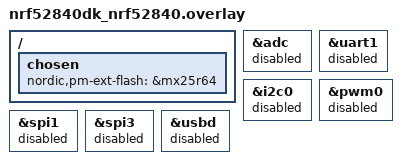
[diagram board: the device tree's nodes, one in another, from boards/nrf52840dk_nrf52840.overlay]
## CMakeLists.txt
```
#
# Copyright (c) 2025 Nordic Semiconductor ASA
#
# SPDX-License-Identifier: LicenseRef-Nordic-5-Clause
#

cmake_minimum_required(VERSION 3.20.0)

find_package(Zephyr HINTS $ENV{ZEPHYR_BASE})

project(matter-contact-sensor)

# Enable GNU STD support.
include(${ZEPHYR_CONNECTEDHOMEIP_MODULE_DIR}/config/nrfconnect/app/enable-gnu-std.cmake)

# NORDIC SDK APP START

# Include all source files that are located in the Matter common directory.
include(${ZEPHYR_NRF_MODULE_DIR}/samples/matter/common/cmake/source_common.cmake)

# Include Data Model utils
include(${ZEPHYR_NRF_MODULE_DIR}/samples/matter/common/cmake/data_model.cmake)

include(${ZEPHYR_NRF_MODULE_DIR}/samples/matter/common/cmake/zap_helpers.cmake)
ncs_get_zap_parent_dir(ZAP_PARENT_DIR)

target_include_directories(app PRIVATE
  src
  ${ZAP_PARENT_DIR}
)

target_sources(app PRIVATE
  src/app_task.cpp
  src/main.cpp
)

ncs_configure_data_model()
# NORDIC SDK APP END
```

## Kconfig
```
#
# Copyright (c) 2025 Nordic Semiconductor
#
# SPDX-License-Identifier: LicenseRef-Nordic-5-Clause
#
mainmenu "Matter nRF Connect Contact Sensor Example Application"

choice OPENTHREAD_NORDIC_LIBRARY_CONFIGURATION
	default OPENTHREAD_NORDIC_LIBRARY_MTD
endchoice

choice OPENTHREAD_DEVICE_TYPE
	default OPENTHREAD_MTD
endchoice

config CHIP_ENABLE_ICD_SUPPORT
	default y

config CHIP_ICD_LIT_SUPPORT
	default y

config CHIP_ICD_SIT_SLOW_POLL_LIMIT
	default 5000

config CHIP_ICD_REPORT_ON_ACTIVE_MODE
	default y

# Reduce Thread TX output power to 0 dBm for SED device
config OPENTHREAD_DEFAULT_TX_POWER
	default 0

source "$(ZEPHYR_CONNECTEDHOMEIP_MODULE_DIR)/config/nrfconnect/chip-module/Kconfig.features"
source "$(ZEPHYR_CONNECTEDHOMEIP_MODULE_DIR)/config/nrfconnect/chip-module/Kconfig.defaults"
source "$(ZEPHYR_NRF_MODULE_DIR)/samples/matter/common/src/Kconfig"
source "Kconfig.zephyr"
```

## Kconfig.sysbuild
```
#
# Copyright (c) 2025 Nordic Semiconductor ASA
#
# SPDX-License-Identifier: LicenseRef-Nordic-5-Clause
#

#### Radio core selection
config NRF_DEFAULT_IPC_RADIO
	default y

# Enable IEEE802.15.4 serialization to network core
# This config automatically pulls in the `overlay-802154.conf` in the ipc_radio image
config NETCORE_IPC_RADIO_IEEE802154
	default y if SOC_SERIES_NRF53

# Enable Bluetooth serialization to network core
# This config automatically pulls in the `bt_hci_ipc.conf` in the ipc_radio image
config NETCORE_IPC_RADIO_BT_HCI_IPC
	default y if SOC_SERIES_NRF53

#### Bootloader
choice BOOTLOADER
	default BOOTLOADER_MCUBOOT
endchoice

if BOOTLOADER_MCUBOOT

#### DFU multi-image support
config DFU_MULTI_IMAGE_PACKAGE_BUILD
	default y

config DFU_MULTI_IMAGE_PACKAGE_APP
	default y

config PM_EXTERNAL_FLASH_MCUBOOT_SECONDARY
	default y

#### DFU network core configuration
if SOC_SERIES_NRF53

config MCUBOOT_UPDATEABLE_IMAGES
	default 2

choice MCUBOOT_MODE
	default MCUBOOT_MODE_OVERWRITE_ONLY
endchoice

choice BOOT_SIGNATURE_TYPE
	default BOOT_SIGNATURE_TYPE_RSA
endchoice

config SECURE_BOOT_NETCORE
	default y

config NETCORE_APP_UPDATE
	default y

config DFU_MULTI_IMAGE_PACKAGE_NET
	default y

endif # SOC_SERIES_NRF53

if BOARD_NRF54L15DK || BOARD_NRF54LM20DK

# Disable checking the external drivers for nRF54L15 and nRF54LM20 DKs.
config PM_OVERRIDE_EXTERNAL_DRIVER_CHECK
	default y

endif # BOARD_NRF54L15DK || BOARD_NRF54LM20DK

endif # BOOTLOADER_MCUBOOT

#### Enable generating factory data
config MATTER_FACTORY_DATA_GENERATE
	default y

source "share/sysbuild/Kconfig"
```

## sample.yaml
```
sample:
  description: Matter Contact Sensor example
  name: Matter Contact Sensor
common:
  tags:
    - sysbuild
    - ci_samples_matter
tests:
  sample.matter.contact_sensor.debug:
    sysbuild: true
    build_only: true
    integration_platforms:
      - nrf54lm20dk/nrf54lm20b/cpuapp
      - nrf54lm20dk/nrf54lm20a/cpuapp
    platform_allow:
      - nrf52840dk/nrf52840
      - nrf5340dk/nrf5340/cpuapp
      - nrf54l15dk/nrf54l15/cpuapp
      - nrf54lm20dk/nrf54lm20b/cpuapp
      - nrf54lm20dk/nrf54lm20a/cpuapp
  sample.matter.contact_sensor.release:
    sysbuild: true
    build_only: true
    extra_args:
      - FILE_SUFFIX=release
    integration_platforms:
      - nrf54lm20dk/nrf54lm20b/cpuapp
      - nrf54lm20dk/nrf54lm20a/cpuapp
    platform_allow:
      - nrf52840dk/nrf52840
      - nrf5340dk/nrf5340/cpuapp
      - nrf54l15dk/nrf54l15/cpuapp
      - nrf54lm20dk/nrf54lm20b/cpuapp
      - nrf54lm20dk/nrf54lm20a/cpuapp
```

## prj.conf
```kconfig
#
# Copyright (c) 2025 Nordic Semiconductor ASA
#
# SPDX-License-Identifier: LicenseRef-Nordic-5-Clause
#

# Enable CHIP
CONFIG_CHIP=y
CONFIG_CHIP_PROJECT_CONFIG="src/chip_project_config.h"
CONFIG_CHIP_DEVICE_PRODUCT_NAME="Matter Contact Sensor"

# Configure ZAP file name
CONFIG_NCS_SAMPLE_MATTER_ZAP_FILE_PATH="${APPLICATION_CONFIG_DIR}/src/default_zap/contact_sensor.zap"

# 32768 == 0x8000 (example Product ID added temporaly,
# as there is no assigned PID on the following list:
# https://github.com/project-chip/connectedhomeip/blob/482e6fd03196a6de45465a90003947ef4b86e0b1/docs/examples/discussion/PID_allocation_for_example_apps.md)
CONFIG_CHIP_DEVICE_PRODUCT_ID=32768
CONFIG_STD_CPP17=y

# Enable Matter pairing automatically on application start.
CONFIG_CHIP_ENABLE_PAIRING_AUTOSTART=y

# Enable Matter extended announcement and increase duration to 1 hour.
CONFIG_CHIP_BLE_EXT_ADVERTISING=y
CONFIG_CHIP_BLE_ADVERTISING_DURATION=60

# Add support for LEDs and buttons on Nordic development kits
CONFIG_DK_LIBRARY=y

# Bluetooth Low Energy configuration
CONFIG_BT_DEVICE_NAME="MatterContact"
CONFIG_BT_DEVICE_NAME_MAX=18

# Suspend devices when the CPU goes into sleep
CONFIG_PM_DEVICE=y

# Other settings
CONFIG_THREAD_NAME=y
CONFIG_MPU_STACK_GUARD=y
CONFIG_RESET_ON_FATAL_ERROR=n
CONFIG_CHIP_LIB_SHELL=y

# Reduce application size
CONFIG_USE_SEGGER_RTT=n

# Enable Factory Data feature
CONFIG_CHIP_FACTORY_DATA=y
CONFIG_CHIP_FACTORY_DATA_BUILD=y
```

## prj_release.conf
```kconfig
#
# Copyright (c) 2025 Nordic Semiconductor ASA
#
# SPDX-License-Identifier: LicenseRef-Nordic-5-Clause
#

# Enable CHIP
CONFIG_CHIP=y
CONFIG_CHIP_PROJECT_CONFIG="src/chip_project_config.h"
CONFIG_CHIP_DEVICE_PRODUCT_NAME="Matter Contact Sensor"

# Configure ZAP file name
CONFIG_NCS_SAMPLE_MATTER_ZAP_FILE_PATH="${APPLICATION_CONFIG_DIR}/src/default_zap/contact_sensor.zap"

# 32768 == 0x8000 (example Product ID added temporaly,
# as there is no assigned PID on the following list:
# https://github.com/project-chip/connectedhomeip/blob/482e6fd03196a6de45465a90003947ef4b86e0b1/docs/examples/discussion/PID_allocation_for_example_apps.md)
CONFIG_CHIP_DEVICE_PRODUCT_ID=32768
CONFIG_STD_CPP17=y

# Enable Matter pairing automatically on application start.
CONFIG_CHIP_ENABLE_PAIRING_AUTOSTART=y

# Enable Matter extended announcement and increase duration to 1 hour.
CONFIG_CHIP_BLE_EXT_ADVERTISING=y
CONFIG_CHIP_BLE_ADVERTISING_DURATION=60

# Add support for LEDs and buttons on Nordic development kits
CONFIG_DK_LIBRARY=y

# Try to disable unused RAM blocks to reduce power consumption
CONFIG_RAM_POWER_DOWN_LIBRARY=y

# Bluetooth Low Energy configuration
CONFIG_BT_DEVICE_NAME="MatterContact"
CONFIG_BT_DEVICE_NAME_MAX=18

# Suspend devices when the CPU goes into sleep
CONFIG_PM_DEVICE=y

# Enable system reset on fatal error
CONFIG_RESET_ON_FATAL_ERROR=y

# Disable all debug features
CONFIG_USE_SEGGER_RTT=n
CONFIG_SHELL=n
CONFIG_OPENTHREAD_SHELL=n
CONFIG_CONSOLE=n
CONFIG_UART_CONSOLE=n
CONFIG_SERIAL=n
CONFIG_LOG=n
CONFIG_LOG_MODE_MINIMAL=n
CONFIG_ASSERT_VERBOSE=n
CONFIG_ASSERT_NO_FILE_INFO=y
CONFIG_PRINTK=n
CONFIG_PRINTK_SYNC=n
CONFIG_THREAD_NAME=n
CONFIG_BOOT_BANNER=n

# Enable Factory Data feature
CONFIG_CHIP_FACTORY_DATA=y
CONFIG_CHIP_FACTORY_DATA_BUILD=y

# Enable Watchdog
CONFIG_NCS_SAMPLE_MATTER_WATCHDOG=y

# Enable LTO to decrease the flash usage.
CONFIG_LTO=y
CONFIG_ISR_TABLES_LOCAL_DECLARATION=y
```

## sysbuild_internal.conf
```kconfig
#
# Copyright (c) 2025 Nordic Semiconductor
#
# SPDX-License-Identifier: LicenseRef-Nordic-5-Clause
#

SB_CONFIG_MATTER=y
SB_CONFIG_PARTITION_MANAGER=n

# Enable the DFU image compression.
SB_CONFIG_MCUBOOT_MODE_OVERWRITE_ONLY=y
SB_CONFIG_MCUBOOT_COMPRESSED_IMAGE_SUPPORT=y
```

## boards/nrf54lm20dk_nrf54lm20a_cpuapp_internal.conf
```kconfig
#
# Copyright (c) 2025 Nordic Semiconductor ASA
#
# SPDX-License-Identifier: LicenseRef-Nordic-5-Clause
#

# Disable SPI
CONFIG_CHIP_SPI_NOR=n
```

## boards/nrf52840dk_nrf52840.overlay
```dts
/*
 * Copyright (c) 2025 Nordic Semiconductor ASA
 *
 * SPDX-License-Identifier: LicenseRef-Nordic-5-Clause
 */

/ {
	chosen {
		nordic,pm-ext-flash = &mx25r64;
	};
};

/* Disable unused peripherals to reduce power consumption */
&adc {
	status = "disabled";
};

&uart1 {
	status = "disabled";
};

&i2c0 {
	status = "disabled";
};

&pwm0 {
	status = "disabled";
};

&spi1 {
	status = "disabled";
};

&spi3 {
	status = "disabled";
};

&usbd {
	status = "disabled";
};
```

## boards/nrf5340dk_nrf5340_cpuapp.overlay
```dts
/*
 * Copyright (c) 2025 Nordic Semiconductor ASA
 *
 * SPDX-License-Identifier: LicenseRef-Nordic-5-Clause
 */

#include <samples/matter/nrf5340_cpuapp_partitions.dtsi>
#include <zephyr/dt-bindings/ipc_service/static_vrings.h>

/* Set IPC thread priority to the highest value to not collide with other threads. */
&ipc0 {
	zephyr,priority = <0 PRIO_COOP>;
};

/ {
	chosen {
		nordic,pm-ext-flash = &mx25r64;
	};
};

&mx25r64 {
	status = "okay";
};

/* Disable unused peripherals to reduce power consumption */
&adc {
	status = "disabled";
};

&i2c1 {
	status = "disabled";
};

&pwm0 {
	status = "disabled";
};

&spi2 {
	status = "disabled";
};

&usbd {
	status = "disabled";
};
```

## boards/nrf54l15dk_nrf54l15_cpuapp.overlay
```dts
/*
 * Copyright (c) 2025 Nordic Semiconductor ASA
 *
 * SPDX-License-Identifier: LicenseRef-Nordic-5-Clause
 */

/ {
	chosen {
		nordic,pm-ext-flash = &mx25r64;
	};

	aliases {
		/* Use watchdog wdt31 as the application watchdog */
		watchdog0 = &wdt31;
	};
};

/* restore full RRAM and SRAM space - by default some parts are dedicated to FLRP */
&cpuapp_rram {
	reg = <0x0 DT_SIZE_K(1524)>;
};

&cpuapp_sram {
	reg = <0x20000000 DT_SIZE_K(256)>;
	ranges = <0x0 0x20000000 0x40000>;
};

&mx25r64 {
	status = "okay";
};

&wdt31 {
	status = "okay";
};
```

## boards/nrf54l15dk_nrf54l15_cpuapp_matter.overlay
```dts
/*
 * Copyright (c) 2025 Nordic Semiconductor ASA
 *
 * SPDX-License-Identifier: LicenseRef-Nordic-5-Clause
 */

/ {
	aliases {
		/* Use watchdog wdt31 as the application watchdog */
		watchdog0 = &wdt31;
	};
};

/* restore full RRAM and SRAM space - by default some parts are dedicated to FLRP */
&cpuapp_rram {
	reg = <0x0 DT_SIZE_K(1524)>;
};

&cpuapp_sram {
	reg = <0x20000000 DT_SIZE_K(256)>;
	ranges = <0x0 0x20000000 0x40000>;
};

/* TODO: re-enable HWFC once it's fixed */
&uart20 {
	/delete-property/ hw-flow-control;
};

&mx25r64 {
	status = "okay";
};

&wdt31 {
	status = "okay";
};
```

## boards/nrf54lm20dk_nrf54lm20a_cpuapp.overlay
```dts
/*
 * Copyright (c) 2025 Nordic Semiconductor ASA
 *
 * SPDX-License-Identifier: LicenseRef-Nordic-5-Clause
 */

#include <samples/matter/nrf54lm20dk_nrf54lm20a_cpuapp_partitions.dtsi>

/ {
	aliases {
		/* Use watchdog wdt31 as the application watchdog */
		watchdog0 = &wdt31;
	};
};

&wdt31 {
	status = "okay";
};
```

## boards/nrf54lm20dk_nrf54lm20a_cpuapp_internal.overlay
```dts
/*
 * Copyright (c) 2025 Nordic Semiconductor ASA
 *
 * SPDX-License-Identifier: LicenseRef-Nordic-5-Clause
 */

/ {
	aliases {
		/* Use watchdog wdt31 as the application watchdog */
		watchdog0 = &wdt31;
	};
};

/* restore full RRAM and SRAM space - by default some parts are dedicated to FLRP */
&cpuapp_rram {
	reg = <0x0 DT_SIZE_K(2036)>;
};

&cpuapp_sram {
	reg = <0x20000000 DT_SIZE_K(512)>;
	ranges = <0x0 0x20000000 0x80000>;
};

&mx25r64 {
	status = "disabled";
};

&wdt31 {
	status = "okay";
};
```

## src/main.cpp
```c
/*
 * Copyright (c) 2025 Nordic Semiconductor ASA
 *
 * SPDX-License-Identifier: LicenseRef-Nordic-5-Clause
 */

#include "app_task.h"

#include <zephyr/logging/log.h>

LOG_MODULE_REGISTER(app, CONFIG_CHIP_APP_LOG_LEVEL);

int main()
{
	CHIP_ERROR err = AppTask::Instance().StartApp();

	LOG_ERR("Exited with code %" CHIP_ERROR_FORMAT, err.Format());
	return err == CHIP_NO_ERROR ? EXIT_SUCCESS : EXIT_FAILURE;
}
```

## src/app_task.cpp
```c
/*
 * Copyright (c) 2025 Nordic Semiconductor ASA
 *
 * SPDX-License-Identifier: LicenseRef-Nordic-5-Clause
 */

#include "app_task.h"

#include "app/matter_init.h"
#include "app/task_executor.h"
#include "board/board.h"
#include "clusters/identify.h"

#include "lib/core/CHIPError.h"
#include <app-common/zap-generated/attributes/Accessors.h>
#include <app/clusters/boolean-state-server/CodegenIntegration.h>

#include <zephyr/logging/log.h>

LOG_MODULE_DECLARE(app, CONFIG_CHIP_APP_LOG_LEVEL);

using namespace ::chip;
using namespace ::chip::app;
using namespace ::chip::DeviceLayer;

namespace
{
constexpr chip::EndpointId kContactSensorEndpointId = 1;

Nrf::Matter::IdentifyCluster sIdentifyCluster(kContactSensorEndpointId);

#define APPLICATION_BUTTON_MASK DK_BTN2_MSK

#ifdef CONFIG_CHIP_ICD_UAT_SUPPORT
#define UAT_BUTTON_MASK DK_BTN3_MSK
#endif
} /* namespace */

void AppTask::ButtonEventHandler(Nrf::ButtonState state, Nrf::ButtonMask hasChanged)
{
	if ((APPLICATION_BUTTON_MASK & hasChanged)) {
		if (state) {
			LOG_INF("Contact sensor detected a contact (button pressed).");
		} else {
			LOG_INF("Contact sensor stopped detecting a contact (button released).");
		}
		Nrf::PostTask([state] {
			auto booleanState =
				app::Clusters::BooleanState::FindClusterOnEndpoint(kContactSensorEndpointId);
			if (booleanState == nullptr) {
				LOG_ERR("Updating contact sensor state failed");
				return;
			}

			booleanState->SetStateValue(state);

			Nrf::GetBoard().GetLED(Nrf::DeviceLeds::LED2).Set(state);
		});
	}
#ifdef CONFIG_CHIP_ICD_UAT_SUPPORT
	if ((UAT_BUTTON_MASK & state & hasChanged)) {
		LOG_INF("ICD UserActiveMode has been triggered.");
		Server::GetInstance().GetICDManager().OnNetworkActivity();
	}
#endif
}

CHIP_ERROR AppTask::Init()
{
	/* Initialize Matter stack */
	ReturnErrorOnFailure(Nrf::Matter::PrepareServer());

	if (!Nrf::GetBoard().Init(ButtonEventHandler)) {
		LOG_ERR("User interface initialization failed.");
		return CHIP_ERROR_INCORRECT_STATE;
	}

	/* Register Matter event handler that controls the connectivity status LED based on the captured Matter network
	 * state. */
	ReturnErrorOnFailure(Nrf::Matter::RegisterEventHandler(Nrf::Board::DefaultMatterEventHandler, 0));

	ReturnErrorOnFailure(sIdentifyCluster.Init());

	return Nrf::Matter::StartServer();
}

CHIP_ERROR AppTask::StartApp()
{
	ReturnErrorOnFailure(Init());

	while (true) {
		Nrf::DispatchNextTask();
	}

	return CHIP_NO_ERROR;
}
```

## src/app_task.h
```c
/*
 * Copyright (c) 2025 Nordic Semiconductor ASA
 *
 * SPDX-License-Identifier: LicenseRef-Nordic-5-Clause
 */

#pragma once

#include "board/board.h"

#include <platform/CHIPDeviceLayer.h>

struct Identify;

class AppTask {
public:
	static AppTask &Instance()
	{
		static AppTask sAppTask;
		return sAppTask;
	};

	CHIP_ERROR StartApp();

private:
	CHIP_ERROR Init();

	static void ButtonEventHandler(Nrf::ButtonState state, Nrf::ButtonMask hasChanged);
};
```
